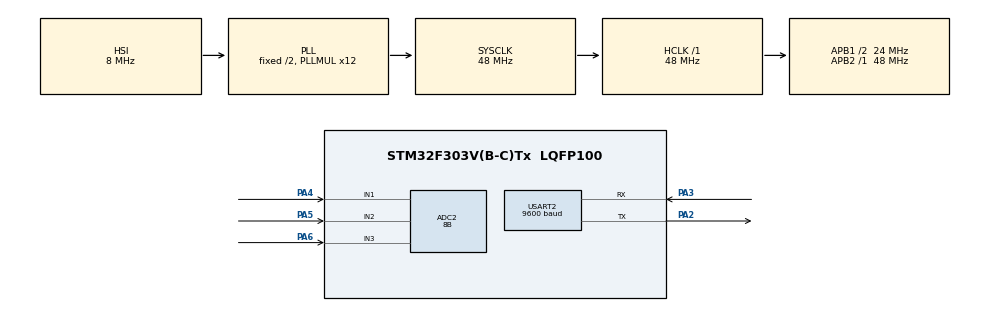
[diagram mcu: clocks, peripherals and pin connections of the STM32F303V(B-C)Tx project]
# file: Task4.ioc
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ADC2.Channel-0\#ChannelRegularConversion=ADC_CHANNEL_1
ADC2.Channel-1\#ChannelRegularConversion=ADC_CHANNEL_2
ADC2.Channel-2\#ChannelRegularConversion=ADC_CHANNEL_3
ADC2.ClockPrescaler=ADC_CLOCK_SYNC_PCLK_DIV4
ADC2.ContinuousConvMode=DISABLE
ADC2.DMAContinuousRequests=ENABLE
ADC2.DiscontinuousConvMode=DISABLE
ADC2.EOCSelection=ADC_EOC_SEQ_CONV
ADC2.ExternalTrigConv=ADC_EXTERNALTRIGCONV_T8_TRGO
ADC2.NbrOfConversion=3
ADC2.NbrOfConversionFlag=1
ADC2.Offset-0\#ChannelRegularConversion=0
ADC2.Offset-1\#ChannelRegularConversion=0
ADC2.Offset-2\#ChannelRegularConversion=0
ADC2.OffsetNumber-0\#ChannelRegularConversion=ADC_OFFSET_NONE
ADC2.OffsetNumber-1\#ChannelRegularConversion=ADC_OFFSET_NONE
ADC2.OffsetNumber-2\#ChannelRegularConversion=ADC_OFFSET_NONE
ADC2.Rank-0\#ChannelRegularConversion=1
ADC2.Rank-1\#ChannelRegularConversion=2
ADC2.Rank-2\#ChannelRegularConversion=3
ADC2.Resolution=ADC_RESOLUTION_8B
ADC2.SamplingTime-0\#ChannelRegularConversion=ADC_SAMPLETIME_601CYCLES_5
ADC2.SamplingTime-1\#ChannelRegularConversion=ADC_SAMPLETIME_601CYCLES_5
ADC2.SamplingTime-2\#ChannelRegularConversion=ADC_SAMPLETIME_601CYCLES_5
ADC2.SamplingTimeOPAMP-1\#ChannelRegularConversion=ADC_SAMPLETIME_19CYCLES_5
ADC2.SamplingTimeOPAMP-2\#ChannelRegularConversion=ADC_SAMPLETIME_19CYCLES_5
Dma.ADC2.0.Direction=DMA_PERIPH_TO_MEMORY
Dma.ADC2.0.Instance=DMA2_Channel1
Dma.ADC2.0.MemDataAlignment=DMA_MDATAALIGN_BYTE
Dma.ADC2.0.MemInc=DMA_MINC_ENABLE
Dma.ADC2.0.Mode=DMA_CIRCULAR
Dma.ADC2.0.PeriphDataAlignment=DMA_PDATAALIGN_BYTE
Dma.ADC2.0.PeriphInc=DMA_PINC_DISABLE
Dma.ADC2.0.Priority=DMA_PRIORITY_LOW
Dma.Request0=ADC2
Mcu.Family=STM32F3
Mcu.Name=STM32F303V(B-C)Tx
Mcu.Package=LQFP100
NVIC.ADC1_2_IRQn=true\:0\:0\:false\:false\:true\:true\:true
NVIC.DMA2_Channel1_IRQn=true\:0\:0\:false\:false\:true\:false\:true
NVIC.PriorityGroup=NVIC_PRIORITYGROUP_0
NVIC.TIM1_TRG_COM_TIM17_IRQn=true\:0\:0\:false\:false\:true\:false\:true
NVIC.TimeBase=TIM1_TRG_COM_TIM17_IRQn
NVIC.TimeBaseIP=TIM17
NVIC.USART2_IRQn=true\:0\:0\:false\:false\:true\:true\:true
PA2.Mode=Asynchronous
PA2.Signal=USART2_TX
PA3.Mode=Asynchronous
PA3.Signal=USART2_RX
PA4.Mode=IN1-Single-Ended
PA4.Signal=ADC2_IN1
PA5.Mode=IN2-Single-Ended
PA5.Signal=ADC2_IN2
PA6.Mode=IN3-Single-Ended
PA6.Signal=ADC2_IN3
PF0-OSC_IN.Mode=HSE-External-Clock-Source
PF0-OSC_IN.Signal=RCC_OSC_IN
ProjectManager.HeapSize=0x200
ProjectManager.StackSize=0x400
ProjectManager.TargetToolchain=STM32CubeIDE
RCC.AHBFreq_Value=48000000
RCC.APB1CLKDivider=RCC_HCLK_DIV2
RCC.APB1Freq_Value=24000000
RCC.APB1TimFreq_Value=48000000
RCC.APB2Freq_Value=48000000
RCC.APB2TimFreq_Value=48000000
RCC.CortexFreq_Value=48000000
RCC.HCLKFreq_Value=48000000
RCC.HSE_VALUE=8000000
RCC.HSI_VALUE=8000000
RCC.LSE_VALUE=32768
RCC.PLLMUL=RCC_PLL_MUL12
RCC.SYSCLKFreq_VALUE=48000000
RCC.SYSCLKSourceVirtual=RCC_SYSCLKSOURCE_PLLCLK
RCC.USBFreq_Value=48000000
TIM8.AutoReloadPreload=TIM_AUTORELOAD_PRELOAD_ENABLE
TIM8.Period=999
TIM8.Prescaler=47999
TIM8.TIM_MasterOutputTrigger=TIM_TRGO_UPDATE
USART2.BaudRate=9600
USART2.VirtualMode-Asynchronous=VM_ASYNC
VP_SYS_VS_tim17.Mode=TIM17
VP_TIM8_VS_ClockSourceINT.Mode=Internal
board=STM32F3DISCOVERY

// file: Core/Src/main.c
/* USER CODE BEGIN Header */
/**
  ******************************************************************************
  * @file           : main.c
  * @brief          : Main program body
  ******************************************************************************
  * @attention
  *
  * <h2><center>&copy; Copyright (c) 2021 STMicroelectronics.
  * All rights reserved.</center></h2>
  *
  * This software component is licensed by ST under BSD 3-Clause license,
  * the "License"; You may not use this file except in compliance with the
  * License. You may obtain a copy of the License at:
  *                        opensource.org/licenses/BSD-3-Clause
  *
  ******************************************************************************
  */
/* USER CODE END Header */
#include "main.h"

ADC_HandleTypeDef hadc2;
DMA_HandleTypeDef hdma_adc2;

TIM_HandleTypeDef htim8;

UART_HandleTypeDef huart2;

void SystemClock_Config(void);
static void MX_GPIO_Init(void);
static void MX_DMA_Init(void);
static void MX_ADC2_Init(void);
static void MX_TIM8_Init(void);
static void MX_USART2_UART_Init(void);

/* USER CODE BEGIN 0 */
uint32_t adc_data[3] = {0, 0, 0};
/* USER CODE END 0 */

int main(void)
{

  /* MCU Configuration--------------------------------------------------------*/

  /* Reset of all peripherals, Initializes the Flash interface and the Systick. */
  HAL_Init();

  /* Configure the system clock */
  SystemClock_Config();

  /* Initialize all configured peripherals */
  MX_GPIO_Init();
  MX_DMA_Init();
  MX_ADC2_Init();
  MX_TIM8_Init();
  MX_USART2_UART_Init();
  /* USER CODE BEGIN 2 */
  HAL_ADC_Start_DMA(&hadc2, adc_data, 3);
  HAL_TIM_Base_Start(&htim8);
  /* USER CODE END 2 */

  /* Infinite loop */
  /* USER CODE BEGIN WHILE */
	HAL_UART_Transmit_IT(&huart2, (uint8_t*)adc_data, 3);

  while (1)
  {
    /* USER CODE END WHILE */

  }
}

void SystemClock_Config(void)
{
  RCC_OscInitTypeDef RCC_OscInitStruct = {0};
  RCC_ClkInitTypeDef RCC_ClkInitStruct = {0};
  RCC_PeriphCLKInitTypeDef PeriphClkInit = {0};

  /** Initializes the RCC Oscillators according to the specified parameters
  * in the RCC_OscInitTypeDef structure.
  */
  RCC_OscInitStruct.OscillatorType = RCC_OSCILLATORTYPE_HSI;
  RCC_OscInitStruct.HSIState = RCC_HSI_ON;
  RCC_OscInitStruct.HSICalibrationValue = RCC_HSICALIBRATION_DEFAULT;
  RCC_OscInitStruct.PLL.PLLState = RCC_PLL_ON;
  RCC_OscInitStruct.PLL.PLLSource = RCC_PLLSOURCE_HSI;
  RCC_OscInitStruct.PLL.PLLMUL = RCC_PLL_MUL12;
  if (HAL_RCC_OscConfig(&RCC_OscInitStruct) != HAL_OK)
  {
    Error_Handler();
  }
  /** Initializes the CPU, AHB and APB buses clocks
  */
  RCC_ClkInitStruct.ClockType = RCC_CLOCKTYPE_HCLK|RCC_CLOCKTYPE_SYSCLK
                              |RCC_CLOCKTYPE_PCLK1|RCC_CLOCKTYPE_PCLK2;
  RCC_ClkInitStruct.SYSCLKSource = RCC_SYSCLKSOURCE_PLLCLK;
  RCC_ClkInitStruct.AHBCLKDivider = RCC_SYSCLK_DIV1;
  RCC_ClkInitStruct.APB1CLKDivider = RCC_HCLK_DIV2;
  RCC_ClkInitStruct.APB2CLKDivider = RCC_HCLK_DIV1;

  if (HAL_RCC_ClockConfig(&RCC_ClkInitStruct, FLASH_LATENCY_1) != HAL_OK)
  {
    Error_Handler();
  }
  PeriphClkInit.PeriphClockSelection = RCC_PERIPHCLK_USART2|RCC_PERIPHCLK_TIM8;
  PeriphClkInit.Usart2ClockSelection = RCC_USART2CLKSOURCE_PCLK1;
  PeriphClkInit.Tim8ClockSelection = RCC_TIM8CLK_HCLK;
  if (HAL_RCCEx_PeriphCLKConfig(&PeriphClkInit) != HAL_OK)
  {
    Error_Handler();
  }
}

static void MX_ADC2_Init(void)
{

  ADC_ChannelConfTypeDef sConfig = {0};

  /** Common config
  */
  hadc2.Instance = ADC2;
  hadc2.Init.ClockPrescaler = ADC_CLOCK_SYNC_PCLK_DIV4;
  hadc2.Init.Resolution = ADC_RESOLUTION_8B;
  hadc2.Init.ScanConvMode = ADC_SCAN_ENABLE;
  hadc2.Init.ContinuousConvMode = DISABLE;
  hadc2.Init.DiscontinuousConvMode = DISABLE;
  hadc2.Init.ExternalTrigConvEdge = ADC_EXTERNALTRIGCONVEDGE_RISING;
  hadc2.Init.ExternalTrigConv = ADC_EXTERNALTRIGCONV_T8_TRGO;
  hadc2.Init.DataAlign = ADC_DATAALIGN_RIGHT;
  hadc2.Init.NbrOfConversion = 3;
  hadc2.Init.DMAContinuousRequests = ENABLE;
  hadc2.Init.EOCSelection = ADC_EOC_SEQ_CONV;
  hadc2.Init.LowPowerAutoWait = DISABLE;
  hadc2.Init.Overrun = ADC_OVR_DATA_OVERWRITTEN;
  if (HAL_ADC_Init(&hadc2) != HAL_OK)
  {
    Error_Handler();
  }
  /** Configure Regular Channel
  */
  sConfig.Channel = ADC_CHANNEL_1;
  sConfig.Rank = ADC_REGULAR_RANK_1;
  sConfig.SingleDiff = ADC_SINGLE_ENDED;
  sConfig.SamplingTime = ADC_SAMPLETIME_601CYCLES_5;
  sConfig.OffsetNumber = ADC_OFFSET_NONE;
  sConfig.Offset = 0;
  if (HAL_ADC_ConfigChannel(&hadc2, &sConfig) != HAL_OK)
  {
    Error_Handler();
  }
  /** Configure Regular Channel
  */
  sConfig.Channel = ADC_CHANNEL_2;
  sConfig.Rank = ADC_REGULAR_RANK_2;
  if (HAL_ADC_ConfigChannel(&hadc2, &sConfig) != HAL_OK)
  {
    Error_Handler();
  }
  /** Configure Regular Channel
  */
  sConfig.Channel = ADC_CHANNEL_3;
  sConfig.Rank = ADC_REGULAR_RANK_3;
  if (HAL_ADC_ConfigChannel(&hadc2, &sConfig) != HAL_OK)
  {
    Error_Handler();
  }

}

static void MX_TIM8_Init(void)
{

  TIM_ClockConfigTypeDef sClockSourceConfig = {0};
  TIM_MasterConfigTypeDef sMasterConfig = {0};

  htim8.Instance = TIM8;
  htim8.Init.Prescaler = 47999;
  htim8.Init.CounterMode = TIM_COUNTERMODE_UP;
  htim8.Init.Period = 999;
  htim8.Init.ClockDivision = TIM_CLOCKDIVISION_DIV1;
  htim8.Init.RepetitionCounter = 0;
  htim8.Init.AutoReloadPreload = TIM_AUTORELOAD_PRELOAD_ENABLE;
  if (HAL_TIM_Base_Init(&htim8) != HAL_OK)
  {
    Error_Handler();
  }
  sClockSourceConfig.ClockSource = TIM_CLOCKSOURCE_INTERNAL;
  if (HAL_TIM_ConfigClockSource(&htim8, &sClockSourceConfig) != HAL_OK)
  {
    Error_Handler();
  }
  sMasterConfig.MasterOutputTrigger = TIM_TRGO_UPDATE;
  sMasterConfig.MasterOutputTrigger2 = TIM_TRGO2_RESET;
  sMasterConfig.MasterSlaveMode = TIM_MASTERSLAVEMODE_DISABLE;
  if (HAL_TIMEx_MasterConfigSynchronization(&htim8, &sMasterConfig) != HAL_OK)
  {
    Error_Handler();
  }

}

static void MX_USART2_UART_Init(void)
{

  huart2.Instance = USART2;
  huart2.Init.BaudRate = 9600;
  huart2.Init.WordLength = UART_WORDLENGTH_8B;
  huart2.Init.StopBits = UART_STOPBITS_1;
  huart2.Init.Parity = UART_PARITY_NONE;
  huart2.Init.Mode = UART_MODE_TX_RX;
  huart2.Init.HwFlowCtl = UART_HWCONTROL_NONE;
  huart2.Init.OverSampling = UART_OVERSAMPLING_16;
  huart2.Init.OneBitSampling = UART_ONE_BIT_SAMPLE_DISABLE;
  huart2.AdvancedInit.AdvFeatureInit = UART_ADVFEATURE_NO_INIT;
  if (HAL_UART_Init(&huart2) != HAL_OK)
  {
    Error_Handler();
  }

}

static void MX_DMA_Init(void)
{

  /* DMA controller clock enable */
  __HAL_RCC_DMA2_CLK_ENABLE();

  /* DMA interrupt init */
  /* DMA2_Channel1_IRQn interrupt configuration */
  HAL_NVIC_SetPriority(DMA2_Channel1_IRQn, 0, 0);
  HAL_NVIC_EnableIRQ(DMA2_Channel1_IRQn);

}

static void MX_GPIO_Init(void)
{

  /* GPIO Ports Clock Enable */
  __HAL_RCC_GPIOF_CLK_ENABLE();
  __HAL_RCC_GPIOA_CLK_ENABLE();

}

/* USER CODE BEGIN 4 */
void HAL_ADC_ConvCpltCallback(ADC_HandleTypeDef* hadc)
{
	HAL_UART_Transmit_IT(&huart2, (uint8_t*)adc_data, 3);
}

void HAL_UART_TxCpltCallback(UART_HandleTypeDef *huart)
{

}
/* USER CODE END 4 */

void HAL_TIM_PeriodElapsedCallback(TIM_HandleTypeDef *htim)
{
  if (htim->Instance == TIM17) {
    HAL_IncTick();
  }
}

void Error_Handler(void)
{
  __disable_irq();
  while (1)
  {
  }
}

/************************ (C) COPYRIGHT STMicroelectronics *****END OF FILE****/
